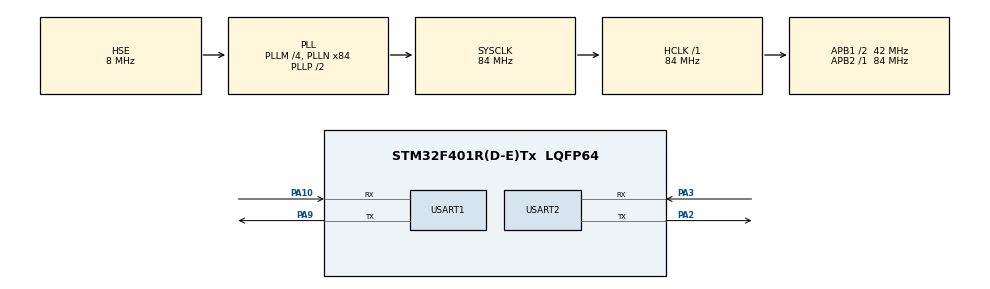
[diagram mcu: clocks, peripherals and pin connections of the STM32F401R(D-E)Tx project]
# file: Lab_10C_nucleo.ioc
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Mcu.Family=STM32F4
Mcu.Name=STM32F401R(D-E)Tx
Mcu.Package=LQFP64
NVIC.PriorityGroup=NVIC_PRIORITYGROUP_4
PA10.Mode=Asynchronous
PA10.Signal=USART1_RX
PA13.Mode=Serial_Wire
PA13.Signal=SYS_JTMS-SWDIO
PA14.Mode=Serial_Wire
PA14.Signal=SYS_JTCK-SWCLK
PA2.Mode=Asynchronous
PA2.Signal=USART2_TX
PA3.Mode=Asynchronous
PA3.Signal=USART2_RX
PA9.Mode=Asynchronous
PA9.Signal=USART1_TX
PH0\ -\ OSC_IN.Mode=HSE-External-Clock-Source
PH0\ -\ OSC_IN.Signal=RCC_OSC_IN
PH1\ -\ OSC_OUT.Mode=HSE-External-Clock-Source
PH1\ -\ OSC_OUT.Signal=RCC_OSC_OUT
ProjectManager.HeapSize=0x200
ProjectManager.StackSize=0x400
ProjectManager.TargetToolchain=MDK-ARM V5.32
RCC.48MHZClocksFreq_Value=42000000
RCC.AHBFreq_Value=84000000
RCC.APB1CLKDivider=RCC_HCLK_DIV2
RCC.APB1Freq_Value=42000000
RCC.APB1TimFreq_Value=84000000
RCC.APB2Freq_Value=84000000
RCC.APB2TimFreq_Value=84000000
RCC.CortexFreq_Value=84000000
RCC.HCLKFreq_Value=84000000
RCC.HSE_VALUE=8000000
RCC.HSI_VALUE=16000000
RCC.LSE_VALUE=32768
RCC.PLLM=4
RCC.PLLN=84
RCC.PLLSourceVirtual=RCC_PLLSOURCE_HSE
RCC.SYSCLKFreq_VALUE=84000000
RCC.SYSCLKSource=RCC_SYSCLKSOURCE_PLLCLK
RCC.VCOOutputFreq_Value=168000000
USART1.VirtualMode=VM_ASYNC
USART2.VirtualMode=VM_ASYNC
board=custom

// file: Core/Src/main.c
/* USER CODE BEGIN Header */
/**
  ******************************************************************************
  * @file           : main.c
  * @brief          : Main program body
  ******************************************************************************
  * @attention
  *
  * Copyright (c) 2026 STMicroelectronics.
  * All rights reserved.
  *
  * This software is licensed under terms that can be found in the LICENSE file
  * in the root directory of this software component.
  * If no LICENSE file comes with this software, it is provided AS-IS.
  *
  ******************************************************************************
  */
/* USER CODE END Header */
#include "main.h"

/* USER CODE BEGIN Includes */
#include<string.h>
#include<stdlib.h>
#include<stdio.h>

/* USER CODE END Includes */

/* Private define -----
-------------------------------------------------------*/

UART_HandleTypeDef huart1;
UART_HandleTypeDef huart2;

void SystemClock_Config(void);
static void MX_GPIO_Init(void);
static void MX_USART1_UART_Init(void);
static void MX_USART2_UART_Init(void);

int main(void)
{

  /* MCU Configuration--------------------------------------------------------*/

  /* Reset of all peripherals, Initializes the Flash interface and the Systick. */
  HAL_Init();

  /* Configure the system clock */
  SystemClock_Config();

  /* Initialize all configured peripherals */
  MX_GPIO_Init();
  MX_USART1_UART_Init();
  MX_USART2_UART_Init();

  /* Infinite loop */
  /* USER CODE BEGIN WHILE */
	char cmd1[] = "AT\r\n";
	uint8_t rx_buffer[128];
	memset(rx_buffer, 0, sizeof(rx_buffer));
	HAL_UART_Transmit(&huart1, (uint8_t*)cmd1, strlen(cmd1), 1000);
	HAL_UART_Receive(&huart1, rx_buffer, sizeof(rx_buffer) - 1, 2000);
	HAL_UART_Transmit(&huart2, rx_buffer, strlen((char*)rx_buffer), 1000);
	HAL_Delay(1000);
	memset(rx_buffer, 0, sizeof(rx_buffer));
	char cmd2[] = "AT+CWMODE=1\r\n";
	HAL_UART_Transmit(&huart1, (uint8_t*)cmd2, strlen(cmd2), 1000);
	HAL_UART_Receive(&huart1, rx_buffer, sizeof(rx_buffer) - 1, 2000);
	HAL_UART_Transmit(&huart2, rx_buffer, strlen((char*)rx_buffer), 1000);

	HAL_Delay(1000);

	char cmd3[] = "AT+CWJAP=\"SNUC\",\"snu12345\"\r\n";
	memset(rx_buffer, 0, sizeof(rx_buffer));
	HAL_UART_Transmit(&huart1, (uint8_t*)cmd3, strlen(cmd3), 1000);
	HAL_UART_Receive(&huart1, rx_buffer, sizeof(rx_buffer) - 1, 20000);
	HAL_UART_Transmit(&huart2, rx_buffer, strlen((char*)rx_buffer), 1000);
	HAL_Delay(1000);

	char cmd6[] = "AT+CIFSR\r\n";
memset(rx_buffer, 0, sizeof(rx_buffer));

HAL_UART_Transmit(&huart1, (uint8_t*)cmd6, strlen(cmd6), 1000);

HAL_UART_Receive(&huart1, rx_buffer, sizeof(rx_buffer) - 1, 2000);

/* Check rx_buffer in the debugger to see the IP response */

HAL_Delay(1000);

	char cmd7[] = "AT+CIPMUX=1\r\n";
	memset(rx_buffer, 0, sizeof(rx_buffer));
	HAL_UART_Transmit(&huart1, (uint8_t*)cmd7, strlen(cmd7), 1000);
	HAL_UART_Receive(&huart1, rx_buffer, sizeof(rx_buffer) - 1, 1000);
	HAL_UART_Transmit(&huart2, rx_buffer, strlen((char*)rx_buffer), 1000);
	HAL_Delay(1000);

	char cmd8[] = "AT+CIPSERVER=1,80\r\n";
	memset(rx_buffer, 0, sizeof(rx_buffer));
	HAL_UART_Transmit(&huart1, (uint8_t*)cmd8, strlen(cmd8), 1000);
	HAL_UART_Receive(&huart1, rx_buffer, sizeof(rx_buffer) - 1, 1000);
	HAL_UART_Transmit(&huart2, rx_buffer, strlen((char*)rx_buffer), 1000);
	HAL_Delay(1000);
	char req[512] = {0};
int idx = 0;

while (1)
{
    uint8_t ch;

    if (HAL_UART_Receive(&huart1, &ch, 1, 100) == HAL_OK)
    {
        if (idx < sizeof(req) - 1)
        {
            req[idx++] = ch;
            req[idx] = '\0';
        }

        char *p = strstr(req, "+IPD,");

        if (p != NULL && strstr(req, "\r\n\r\n") != NULL)
{
	char msg[] = "\r\nHTTP REQUEST DETECTED\r\n";
HAL_UART_Transmit(&huart2, (uint8_t*)msg, strlen(msg), 1000);
    int link_id = -1;
    int data_len = 0;

    if (sscanf(p, "+IPD,%d,%d:", &link_id, &data_len) != 2)
    {
        memset(req, 0, sizeof(req));
        idx = 0;
        continue;
    }

    if (link_id < 0 || link_id > 4)
    {
        memset(req, 0, sizeof(req));
        idx = 0;
        continue;
    }

            char body[] =
                "<html><body><h1>STM32 IoT Node</h1>"
                "<p>Hello from STM32</p></body></html>";

            char response[512];

            snprintf(response, sizeof(response),
                "HTTP/1.1 200 OK\r\n"
                "Content-Type: text/html\r\n"
                "Content-Length: %u\r\n"
                "Connection: close\r\n\r\n%s",
                (unsigned int)strlen(body), body);

            char cmd[40];

            snprintf(cmd, sizeof(cmd), "AT+CIPSEND=%d,%u\r\n",
                link_id, (unsigned int)strlen(response));

            HAL_UART_Transmit(&huart1, (uint8_t *)cmd,
                              strlen(cmd), 1000);

            uint32_t start = HAL_GetTick();
            uint8_t prompt = 0;

            while (HAL_GetTick() - start < 5000)
            {
                if (HAL_UART_Receive(&huart1, &ch, 1, 100) == HAL_OK)
                {
                    if (ch == '>')
                    {
                        prompt = 1;
                        break;
                    }
                }
            }

            if (prompt)
            {
                HAL_UART_Transmit(&huart1, (uint8_t *)response,
                                  strlen(response), 3000);

                HAL_Delay(500);

                snprintf(cmd, sizeof(cmd), "AT+CIPCLOSE=%d\r\n",
                         link_id);

                HAL_UART_Transmit(&huart1, (uint8_t *)cmd,
                                  strlen(cmd), 1000);
            }

            memset(req, 0, sizeof(req));
            idx = 0;
        }

        if (idx >= sizeof(req) - 1)
        {
            memset(req, 0, sizeof(req));
            idx = 0;
        }
    }
}
  /* USER CODE END 3 */
}

void SystemClock_Config(void)
{
  RCC_OscInitTypeDef RCC_OscInitStruct = {0};
  RCC_ClkInitTypeDef RCC_ClkInitStruct = {0};

  /** Configure the main internal regulator output voltage
  */
  __HAL_RCC_PWR_CLK_ENABLE();
  __HAL_PWR_VOLTAGESCALING_CONFIG(PWR_REGULATOR_VOLTAGE_SCALE2);

  /** Initializes the RCC Oscillators according to the specified parameters
  * in the RCC_OscInitTypeDef structure.
  */
  RCC_OscInitStruct.OscillatorType = RCC_OSCILLATORTYPE_HSE;
  RCC_OscInitStruct.HSEState = RCC_HSE_BYPASS;
  RCC_OscInitStruct.PLL.PLLState = RCC_PLL_ON;
  RCC_OscInitStruct.PLL.PLLSource = RCC_PLLSOURCE_HSE;
  RCC_OscInitStruct.PLL.PLLM = 4;
  RCC_OscInitStruct.PLL.PLLN = 84;
  RCC_OscInitStruct.PLL.PLLP = RCC_PLLP_DIV2;
  RCC_OscInitStruct.PLL.PLLQ = 4;
  if (HAL_RCC_OscConfig(&RCC_OscInitStruct) != HAL_OK)
  {
    Error_Handler();
  }

  /** Initializes the CPU, AHB and APB buses clocks
  */
  RCC_ClkInitStruct.ClockType = RCC_CLOCKTYPE_HCLK|RCC_CLOCKTYPE_SYSCLK
                              |RCC_CLOCKTYPE_PCLK1|RCC_CLOCKTYPE_PCLK2;
  RCC_ClkInitStruct.SYSCLKSource = RCC_SYSCLKSOURCE_PLLCLK;
  RCC_ClkInitStruct.AHBCLKDivider = RCC_SYSCLK_DIV1;
  RCC_ClkInitStruct.APB1CLKDivider = RCC_HCLK_DIV2;
  RCC_ClkInitStruct.APB2CLKDivider = RCC_HCLK_DIV1;

  if (HAL_RCC_ClockConfig(&RCC_ClkInitStruct, FLASH_LATENCY_2) != HAL_OK)
  {
    Error_Handler();
  }
}

static void MX_USART1_UART_Init(void)
{

  huart1.Instance = USART1;
  huart1.Init.BaudRate = 115200;
  huart1.Init.WordLength = UART_WORDLENGTH_8B;
  huart1.Init.StopBits = UART_STOPBITS_1;
  huart1.Init.Parity = UART_PARITY_NONE;
  huart1.Init.Mode = UART_MODE_TX_RX;
  huart1.Init.HwFlowCtl = UART_HWCONTROL_NONE;
  huart1.Init.OverSampling = UART_OVERSAMPLING_16;
  if (HAL_UART_Init(&huart1) != HAL_OK)
  {
    Error_Handler();
  }

}

static void MX_USART2_UART_Init(void)
{

  huart2.Instance = USART2;
  huart2.Init.BaudRate = 115200;
  huart2.Init.WordLength = UART_WORDLENGTH_8B;
  huart2.Init.StopBits = UART_STOPBITS_1;
  huart2.Init.Parity = UART_PARITY_NONE;
  huart2.Init.Mode = UART_MODE_TX_RX;
  huart2.Init.HwFlowCtl = UART_HWCONTROL_NONE;
  huart2.Init.OverSampling = UART_OVERSAMPLING_16;
  if (HAL_UART_Init(&huart2) != HAL_OK)
  {
    Error_Handler();
  }

}

static void MX_GPIO_Init(void)
{

  /* GPIO Ports Clock Enable */
  __HAL_RCC_GPIOH_CLK_ENABLE();
  __HAL_RCC_GPIOA_CLK_ENABLE();

}

void Error_Handler(void)
{
  __disable_irq();
  while (1)
  {
  }
}
